# SC32F12XRX48 register map
File version: 1.0
CPU: CM0+ r0p1, little endian, MPU, no FPU, 4 interrupt priority bits
Registers are 32-bit, read-write, reset 0x0 unless marked. A register's access mark holds for its fields unless they carry their own. Offsets are from the block's base; [hi:lo] are bit positions; {n}, {i} and the like mark numbered series.

## DMA0 — DMA0 controller
Base 0x40010800
Same registers: DMA1 0x40010840
0x00 SADR — Source address data register
0x04 DADR — Destination address data register
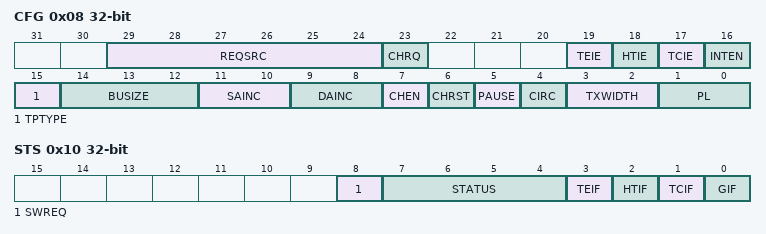
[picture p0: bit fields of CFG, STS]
0x08 CFG — DMA Control Configuratio register
  [29:24] REQSRC — Requests of source channel
  [23] CHRQ — Channel request another
  [19] TEIE — transfer error interrut enable
  [18] HTIE — Half transfer interrut enable
  [17] TCIE — Transfer complete interrut enable
  [16] INTEN — Intrerrut mask
  [15] TPTYPE — Transfer Type
  [14:12] BUSIZE — Burst Transfer size
  [11:10] SAINC — Soucre address increment mode
  [9:8] DAINC — Destination address increment mode
  [7] CHEN — Channel enable
  [6] CHRST — Channel reset
  [5] PAUSE — Channel pause
  [4] CIRC — Cyclical pattern control bit
  [3:2] TXWIDTH — Transfer width of the working registers
  [1:0] PL — Channel priority
0x0C CNT — DMA channel counter register
  [31:0] DMACNT
0x10 STS — DMA channel status register
  [8] SWREQ — Software request
  [7:4] STATUS ro — DMA stauts
  [3] TEIF — Transfer error interrupt flag
  [2] HTIF — Half transfer interrupt flag
  [1] TCIF — Transfer complete interrupt flag
  [0] GIF ro — Global interrut flag

## GPIOA — General-purpose I/Os A
Base 0x40011000
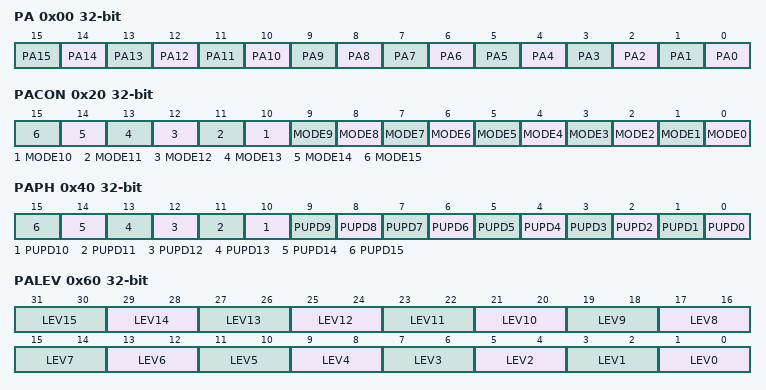
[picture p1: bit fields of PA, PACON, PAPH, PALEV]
0x00 PA — GPIOA port data register
  [n] PA{n} (n=0..15) — Port A data {n} bits
0x20 PACON — GPIOA port control register
  [n] MODE{n} (n=0..15) — Port {n} mode bits
0x40 PAPH — GPIOA port pull up resistor register
  [n] PUPD{n} (n=0..15) — Port {n} pull up resistor bits
0x60 PALEV — GPIOA port output level register
  [2n+1:2n] LEV{n} (n=0..15) — Port {n} level bit

## GPIOB — General-purpose I/Os B
Base 0x40011100
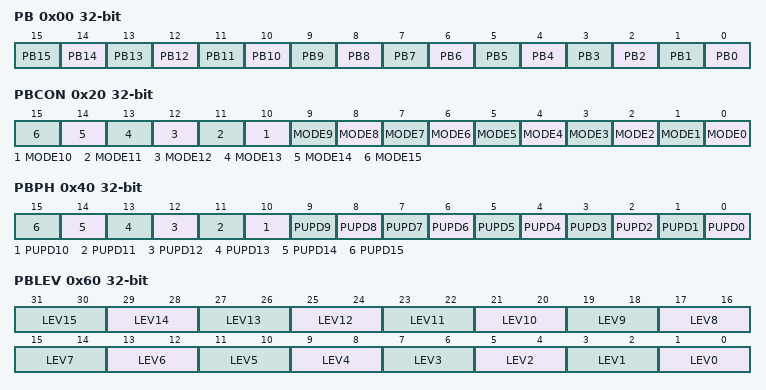
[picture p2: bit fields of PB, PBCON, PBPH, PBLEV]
0x00 PB — GPIOB port data register
  [n] PB{n} (n=0..15) — Port B data {n} bits
0x20 PBCON — GPIOB port control register
  [n] MODE{n} (n=0..15) — Port {n} mode bits
0x40 PBPH — GPIOB port pull up resistor register
  [n] PUPD{n} (n=0..15) — Port {n} pull up resistor bits
0x60 PBLEV — GPIOB port output level register
  [2n+1:2n] LEV{n} (n=0..15) — Port {n} level bit

## GPIOC — General-purpose I/Os C
Base 0x40011200
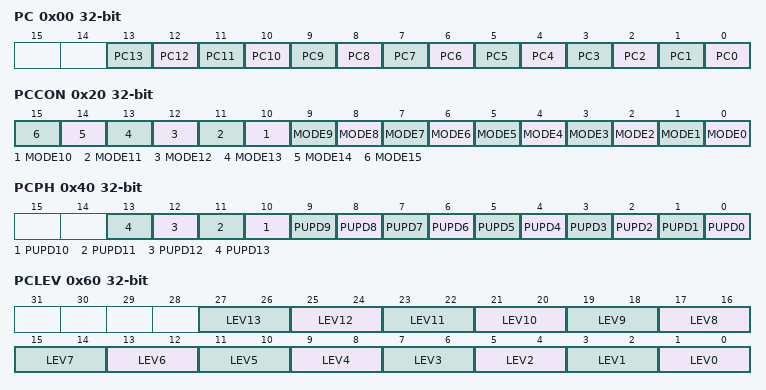
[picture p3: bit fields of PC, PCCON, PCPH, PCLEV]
0x00 PC — GPIOC port data register
  [n] PC{n} (n=0..13) — Port C data {n} bits
0x20 PCCON — GPIOC port control register
  [n] MODE{n} (n=0..15) — Port {n} mode bits
0x40 PCPH — GPIOC port pull up resistor register
  [n] PUPD{n} (n=0..13) — Port {n} pull up resistor bits
0x60 PCLEV — GPIOC port output level register
  [2n+1:2n] LEV{n} (n=0..13) — Port {n} level bit

## INT — Interrupt/event controller
Base 0x40011800
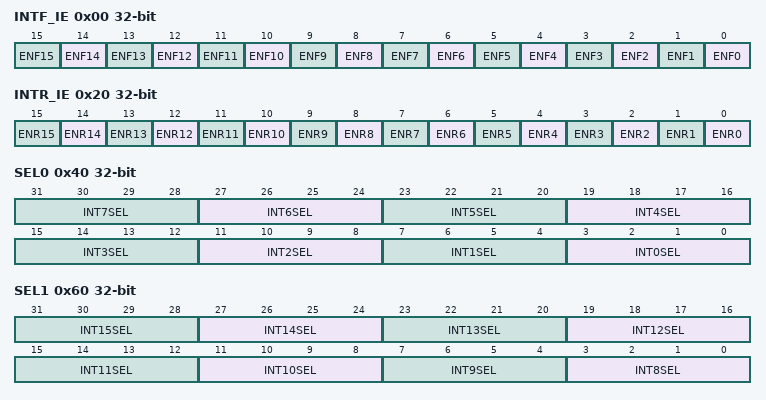
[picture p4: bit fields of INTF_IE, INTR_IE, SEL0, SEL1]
0x00 INTF_IE — External Interrupt falling trigger enable register
  [n] ENF{n} (n=0..15) — falling trigger event enable bit{n}
0x20 INTR_IE — External Interrupt Rising trigger enable register
  [n] ENR{n} (n=0..15) — Rising trigger event enable bit{n}
0x40 SEL0 — External Interrupt Select port register0
  [4n+3:4n] INT{n}SEL (n=0..7) — EXTI port{n} select
0x60 SEL1 — EXTI Select port register1
  [4n-29:4n-32] INT{n}SEL (n=8..15) — EXTI port{n} select
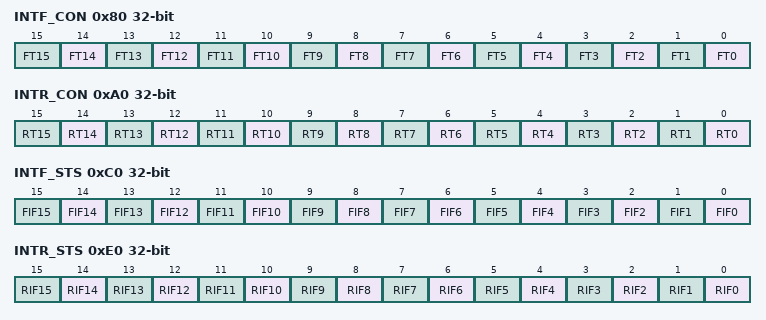
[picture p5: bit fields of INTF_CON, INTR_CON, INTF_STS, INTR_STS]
0x80 INTF_CON — External Interrupt falling control register
  [n] FT{n} (n=0..15) — configurable event inputs x falling edge pending bit.
0xA0 INTR_CON — External Interrupt rising control register
  [n] RT{n} (n=0..15) — configurable event inputs x rising edge pending bit.
0xC0 INTF_STS — External Interrupt falling interrupt status register
  [n] FIF{n} (n=0..15) — Falling intput flag port{n}
0xE0 INTR_STS — EXTI rising interrupt status register
  [n] RIF{n} (n=0..15) — Rising intput flag port{n}

## UART0 — Universal synchronous asynchronous receiver transmitter
Base 0x40020020
Same registers: UART1 0x40020080, UART5 0x400200A0, UART2 0x40021020, UART4 0x40021080, UART3 0x40022020
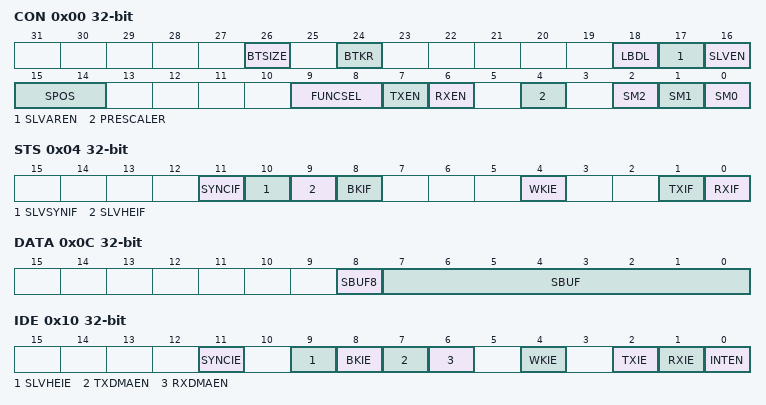
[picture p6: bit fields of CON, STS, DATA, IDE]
0x00 CON — Control register
  [26] BTSIZE — LIN mode break size
  [24] BTKR — LIN mode break trig
  [18] LBDL — LIN break detection length
  [17] SLVAREN — The baud rate automatic resynchronization was enabled
  [16] SLVEN — Select the master or slave mode
  [15:14] SPOS — Mapping the IO
  [9:8] FUNCSEL — Function Selection
  [7] TXEN — Transmit allowed enable
  [6] RXEN — Receiving allowed enable
  [4] PRESCALER — Baud rate multiplier setting
  [2] SM2 — UART mode enable
  [1] SM1 — UART mode enable
  [0] SM0 — UART mode enable
0x04 STS — Stauts register
  [11] SYNCIF — LIN mode baud rate synchronization complete flag enable bi
  [10] SLVSYNIF — LIN synchronizes domain status bits from the slave machine
  [9] SLVHEIF ro — LIN slave header error flag
  [8] BKIF ro — LIN Break interrupt flag
  [4] WKIE — Wake up the UART interrupt flag
  [1] TXIF — Transmit interrupt flag
  [0] RXIF — Receive interrupt flag
0x08 BAUD — Baud rate register
  [15:0] BAUD — Baud rate configuration
0x0C DATA
  [8] SBUF8 — Serial port data9 buffer value
  [7:0] SBUF — Serial port data buffer value
0x10 IDE — interrut enable register
  [11] SYNCIE — LIN mode baud rate synchronization complete flag enable bit
  [9] SLVHEIE — LIN slave header error flag Interrupt enable
  [8] BKIE — LIN mode break Interrupt enable
  [7] TXDMAEN — DMA Transmit data Interrupt enable
  [6] RXDMAEN — DMA receiver data Interrupt enable
  [4] WKIE — Weak up Interrupt enable
  [2] TXIE — Transmit Interrupt enable
  [1] RXIE — Receiver Interrupt enable
  [0] INTEN — Interrupt enable
